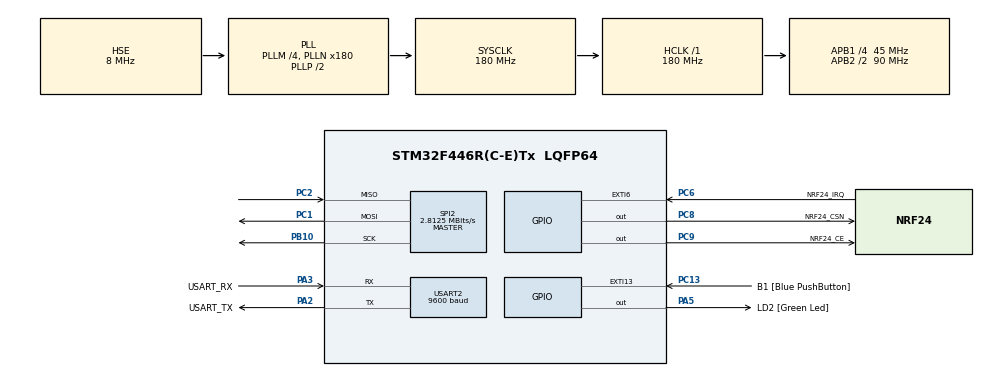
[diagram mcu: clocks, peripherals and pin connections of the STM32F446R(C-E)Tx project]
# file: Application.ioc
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Mcu.Family=STM32F4
Mcu.Name=STM32F446R(C-E)Tx
Mcu.Package=LQFP64
NVIC.EXTI9_5_IRQn=true\:0\:0\:false\:false\:true\:true\:true
NVIC.PriorityGroup=NVIC_PRIORITYGROUP_0
NVIC.TIM6_DAC_IRQn=true\:0\:0\:false\:false\:true\:true\:true
NVIC.TIM7_IRQn=true\:0\:0\:false\:false\:true\:true\:true
NVIC.USART2_IRQn=true\:0\:0\:false\:false\:true\:true\:true
PA13.GPIO_Label=TMS
PA13.Mode=Serial_Wire
PA13.Signal=SYS_JTMS-SWDIO
PA14.GPIO_Label=TCK
PA14.Mode=Serial_Wire
PA14.Signal=SYS_JTCK-SWCLK
PA2.GPIO_Label=USART_TX
PA2.Mode=Asynchronous
PA2.Signal=USART2_TX
PA3.GPIO_Label=USART_RX
PA3.Mode=Asynchronous
PA3.Signal=USART2_RX
PA5.GPIO_Label=LD2 [Green Led]
PA5.Signal=GPIO_Output
PB10.Mode=Full_Duplex_Master
PB10.Signal=SPI2_SCK
PB3.GPIO_Label=SWO
PB3.Signal=SYS_JTDO-SWO
PC1.Mode=Full_Duplex_Master
PC1.Signal=SPI2_MOSI
PC13.GPIO_Label=B1 [Blue PushButton]
PC13.GPIO_ModeDefaultEXTI=GPIO_MODE_IT_FALLING
PC13.Signal=GPXTI13
PC14-OSC32_IN.Mode=LSE-External-Oscillator
PC14-OSC32_IN.Signal=RCC_OSC32_IN
PC15-OSC32_OUT.Mode=LSE-External-Oscillator
PC15-OSC32_OUT.Signal=RCC_OSC32_OUT
PC2.Mode=Full_Duplex_Master
PC2.Signal=SPI2_MISO
PC6.GPIO_Label=NRF24_IRQ
PC6.GPIO_ModeDefaultEXTI=GPIO_MODE_IT_FALLING
PC6.GPIO_PuPd=GPIO_PULLUP
PC6.Signal=GPXTI6
PC8.GPIO_Label=NRF24_CSN
PC8.Signal=GPIO_Output
PC9.GPIO_Label=NRF24_CE
PC9.Signal=GPIO_Output
PH0-OSC_IN.Mode=HSE-External-Oscillator
PH0-OSC_IN.Signal=RCC_OSC_IN
PH1-OSC_OUT.Mode=HSE-External-Oscillator
PH1-OSC_OUT.Signal=RCC_OSC_OUT
ProjectManager.HeapSize=0x200
ProjectManager.StackSize=0x400
ProjectManager.TargetToolchain=STM32CubeIDE
RCC.48MHZClocksFreq_Value=84000000
RCC.AHBFreq_Value=180000000
RCC.APB1CLKDivider=RCC_HCLK_DIV4
RCC.APB1Freq_Value=45000000
RCC.APB1TimFreq_Value=90000000
RCC.APB2CLKDivider=RCC_HCLK_DIV2
RCC.APB2Freq_Value=90000000
RCC.APB2TimFreq_Value=180000000
RCC.CortexFreq_Value=180000000
RCC.FLatency-AdvancedSettings=FLASH_LATENCY_5
RCC.HCLKFreq_Value=180000000
RCC.HSE_VALUE=8000000
RCC.HSI_VALUE=16000000
RCC.PLLM=4
RCC.PLLN=180
RCC.PLLSourceVirtual=RCC_PLLSOURCE_HSE
RCC.SYSCLKFreq_VALUE=180000000
RCC.SYSCLKSource=RCC_SYSCLKSOURCE_PLLCLK
RCC.USBFreq_Value=180000000
RCC.VCOOutputFreq_Value=360000000
SPI2.BaudRatePrescaler=SPI_BAUDRATEPRESCALER_16
SPI2.CalculateBaudRate=2.8125 MBits/s
SPI2.Direction=SPI_DIRECTION_2LINES
SPI2.Mode=SPI_MODE_MASTER
SPI2.VirtualType=VM_MASTER
TIM6.Period=9999
TIM6.Prescaler=8999
TIM7.Period=29999
TIM7.Prescaler=59999
USART2.BaudRate=9600
USART2.VirtualMode=VM_ASYNC
VP_TIM6_VS_ClockSourceINT.Mode=Enable_Timer
VP_TIM7_VS_ClockSourceINT.Mode=Enable_Timer
board=NUCLEO-F446RE

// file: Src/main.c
/* USER CODE BEGIN Header */
/**
  ******************************************************************************
  * @file           : main.c
  * @brief          : Main program body
  ******************************************************************************
  * @attention
  *
  * <h2><center>&copy; Copyright (c) 2021 STMicroelectronics.
  * All rights reserved.</center></h2>
  *
  * This software component is licensed by ST under BSD 3-Clause license,
  * the "License"; You may not use this file except in compliance with the
  * License. You may obtain a copy of the License at:
  *                        opensource.org/licenses/BSD-3-Clause
  *
  ******************************************************************************
  */
/* USER CODE END Header */

#include "main.h"
#include "spi.h"
#include "tim.h"
#include "usart.h"
#include "gpio.h"

/* USER CODE BEGIN PV */
CommandLineInterfaceControllerHandle_t hCLI;
ApplicationHandler_t hApplication;

uint8_t myRxData[1000u];
uint8_t myTxData[1000u];
/* USER CODE END PV */

void SystemClock_Config(void);

int main(void)
{

  /* MCU Configuration--------------------------------------------------------*/

  /* Reset of all peripherals, Initializes the Flash interface and the Systick. */
  HAL_Init();

  /* Configure the system clock */
  SystemClock_Config();

  /* Initialize all configured peripherals */
  MX_GPIO_Init();
  MX_USART2_UART_Init();
  MX_SPI2_Init();
  MX_TIM6_Init();
  MX_TIM7_Init();
  /* USER CODE BEGIN 2 */
  CommandLineInterfaceController_Init(&hCLI);
  ApplicationManager_Init(&hApplication);
  NRF24_begin(NRF24_CE_GPIO_Port, NRF24_CSN_Pin, NRF24_CE_Pin, hspi2);

  CommandLineInterfaceController_WriteMessage(&hCLI, "COMMAND LINE INTERFACE\r\n");

  HAL_UART_Receive_IT(&huart2, (uint8_t*) &hCLI.pCLI_Buffer[hCLI.CLI_BufferHead], 1u);
  HAL_TIM_Base_Start_IT(&htim6);
  HAL_TIM_Base_Start_IT(&htim7);
  NRF24_startListening();

  ApplicationManager_StateMachine(&hApplication);
  /* USER CODE END 2 */

  /* Infinite loop */
  while (1)
  {

  }
}

void SystemClock_Config(void)
{
  RCC_OscInitTypeDef RCC_OscInitStruct = {0};
  RCC_ClkInitTypeDef RCC_ClkInitStruct = {0};

  /** Configure the main internal regulator output voltage
  */
  __HAL_RCC_PWR_CLK_ENABLE();
  __HAL_PWR_VOLTAGESCALING_CONFIG(PWR_REGULATOR_VOLTAGE_SCALE1);
  /** Initializes the CPU, AHB and APB busses clocks
  */
  RCC_OscInitStruct.OscillatorType = RCC_OSCILLATORTYPE_HSE;
  RCC_OscInitStruct.HSEState = RCC_HSE_ON;
  RCC_OscInitStruct.PLL.PLLState = RCC_PLL_ON;
  RCC_OscInitStruct.PLL.PLLSource = RCC_PLLSOURCE_HSE;
  RCC_OscInitStruct.PLL.PLLM = 4;
  RCC_OscInitStruct.PLL.PLLN = 180;
  RCC_OscInitStruct.PLL.PLLP = RCC_PLLP_DIV2;
  RCC_OscInitStruct.PLL.PLLQ = 2;
  RCC_OscInitStruct.PLL.PLLR = 2;
  if (HAL_RCC_OscConfig(&RCC_OscInitStruct) != HAL_OK)
  {
    Error_Handler();
  }
  /** Activate the Over-Drive mode
  */
  if (HAL_PWREx_EnableOverDrive() != HAL_OK)
  {
    Error_Handler();
  }
  /** Initializes the CPU, AHB and APB busses clocks
  */
  RCC_ClkInitStruct.ClockType = RCC_CLOCKTYPE_HCLK|RCC_CLOCKTYPE_SYSCLK
                              |RCC_CLOCKTYPE_PCLK1|RCC_CLOCKTYPE_PCLK2;
  RCC_ClkInitStruct.SYSCLKSource = RCC_SYSCLKSOURCE_PLLCLK;
  RCC_ClkInitStruct.AHBCLKDivider = RCC_SYSCLK_DIV1;
  RCC_ClkInitStruct.APB1CLKDivider = RCC_HCLK_DIV4;
  RCC_ClkInitStruct.APB2CLKDivider = RCC_HCLK_DIV2;

  if (HAL_RCC_ClockConfig(&RCC_ClkInitStruct, FLASH_LATENCY_5) != HAL_OK)
  {
    Error_Handler();
  }
}

void Error_Handler(void)
{
}

/************************ (C) COPYRIGHT STMicroelectronics *****END OF FILE****/
